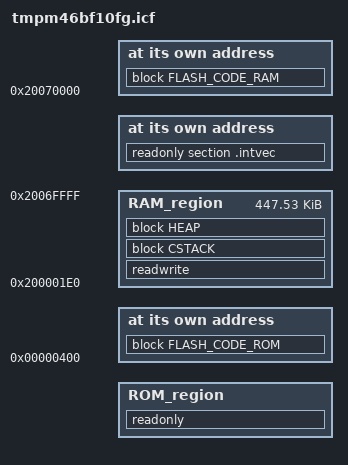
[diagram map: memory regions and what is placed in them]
/*###ICF### Section handled by ICF editor, don't touch! ****/
/*-Editor annotation file-*/
/* IcfEditorFile="$TOOLKIT_DIR$\config\ide\IcfEditor\cortex_v1_0.xml" */
/*-Specials-*/
if (!isdefinedsymbol(MBED_APP_START)) { define symbol MBED_APP_START = 0x00000000; }
if (!isdefinedsymbol(MBED_APP_SIZE)) { define symbol MBED_APP_SIZE = 0x100000; }
define symbol __ICFEDIT_intvec_start__ = MBED_APP_START;
/*-Memory Regions-*/
define symbol __ICFEDIT_region_ROM_start__   = MBED_APP_START;
define symbol __ICFEDIT_region_ROM_end__     = MBED_APP_START + MBED_APP_SIZE - 1;
define symbol __ICFEDIT_region_RAM_start__   = 0x200001E0;
define symbol __ICFEDIT_region_RAM_end__     = 0x2006FFFF;
define symbol __ICFEDIT_region_BRAM_start__  = 0x20070000;
define symbol __ICFEDIT_region_BRAM_end__    = 0x200807FF;
/*-Sizes-*/
/*Heap 1/4 of ram and stack 1/8*/
define symbol __ICFEDIT_size_cstack__   = 0x10000;
define symbol __ICFEDIT_size_heap__     = 0x20000;
/**** End of ICF editor section. ###ICF###*/

define memory mem with size = 4G;
define region ROM_region   = mem:[from __ICFEDIT_region_ROM_start__   to __ICFEDIT_region_ROM_end__];
define region RAM_region   = mem:[from __ICFEDIT_region_RAM_start__   to __ICFEDIT_region_RAM_end__];

define block CSTACK    with alignment = 8, size = __ICFEDIT_size_cstack__   { };
define block HEAP      with alignment = 8, size = __ICFEDIT_size_heap__     { };

define block FLASH_CODE_ROM  {section FLASH_ROM_init object flash_api.o, section .text_init object tmpm46b_fc.o}; 
define block FLASH_CODE_RAM  {section FLASH_ROM object flash_api.o, section .text object tmpm46b_fc.o};

initialize by copy { readwrite };
initialize manually { section FLASH_ROM object flash_api.o, section .text object tmpm46b_fc.o};
do not initialize  { section .noinit };

place at address mem:__ICFEDIT_intvec_start__ { readonly section .intvec };
place at address mem: 0x400 { block FLASH_CODE_ROM };
place at address mem: 0x20070000 { block FLASH_CODE_RAM };
place in RAM_region   { readwrite,
                        block CSTACK, block HEAP };
place in ROM_region   { readonly };
